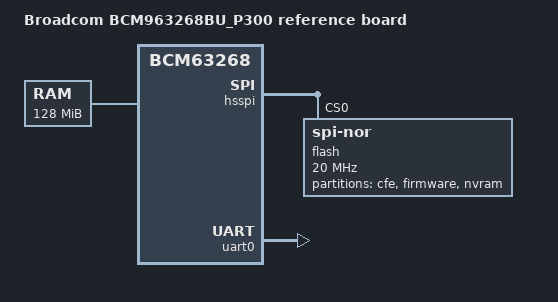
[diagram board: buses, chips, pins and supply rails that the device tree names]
/dts-v1/;

#include "bcm63268.dtsi"

/ {
	model = "Broadcom BCM963268BU_P300 reference board";
	compatible = "brcm,bcm963268bu-p300", "brcm,bcm63268";

	memory {
		device_type = "memory";
		reg = <0x00000000 0x08000000>;
	};

        chosen {
                bootargs = "console=ttyS0,115200";
                stdout-path = &uart0;
        };
};

&hsspi {
	status = "okay";

	flash@0 {
		compatible = "jedec,spi-nor";
		spi-max-frequency = <20000000>;
		spi-tx-bus-width = <2>;
		spi-rx-bus-width = <2>;
		reg = <0>;

		#address-cells = <1>;
		#size-cells = <1>;

		partitions {
			compatible = "fixed-partitions";
			#address-cells = <1>;
			#size-cells = <1>;

			partition@0 {
				reg = <0x000000 0x010000>;
				label = "cfe";
				read-only;
			};

			partition@10000 {
				compatible = "brcm,bcm963xx-imagetag";
				reg = <0x010000 0x7e0000>;
				label = "firmware";
			};

			partition@7f0000 {
				reg = <0x7f0000 0x010000>;
				label = "nvram";
			};
		};
	};
};

&uart0 {
	status = "okay";
};
